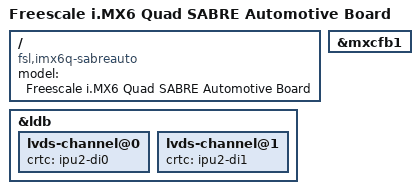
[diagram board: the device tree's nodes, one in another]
/*
 * Copyright 2012-2015 Freescale Semiconductor, Inc.
 * Copyright 2011 Linaro Ltd.
 *
 * The code contained herein is licensed under the GNU General Public
 * License. You may obtain a copy of the GNU General Public License
 * Version 2 or later at the following locations:
 *
 * http://www.opensource.org/licenses/gpl-license.html
 * http://www.gnu.org/copyleft/gpl.html
 */

/dts-v1/;

#define CONFIG_MX6ES1MFG 0
#define CONFIG_MX6ES1OTG 1
#include "imx6q-es1.dtsi"
#include "imx6qdl-sabreauto-es1.dtsi"

/ {
	model = "Freescale i.MX6 Quad SABRE Automotive Board";
	compatible = "fsl,imx6q-sabreauto", "fsl,imx6q";
};

&ldb {
	lvds-channel@0 {
		crtc = "ipu2-di0";
	};
	lvds-channel@1 {
		crtc = "ipu2-di1";
	};
};
&mxcfb1 {
	status = "okay";
};
#if 0
&mxcfb2 {
	status = "okay";
};
&mxcfb3 {
	status = "okay";
};
&mxcfb4 {
	status = "okay";
};
&sata {
	status = "okay";
};
#endif
